# USB_USB_DWC3_53910000h register map
Vendor: Texas Instruments
Peripheral module from a debugger description file (folder AM261x).
Registers are 32-bit, read-write, reset 0x0 unless marked. A register's access mark holds for its fields unless they carry their own. Offsets are as the file gives them; lines under a group give offsets from that group; [hi:lo] are bit positions; {n}, {i} and the like mark numbered series; 'fields as' and 'values as' point back to an identical list; <NAME> marks a mode.

## USB_DWC3 (part 1 of 2)
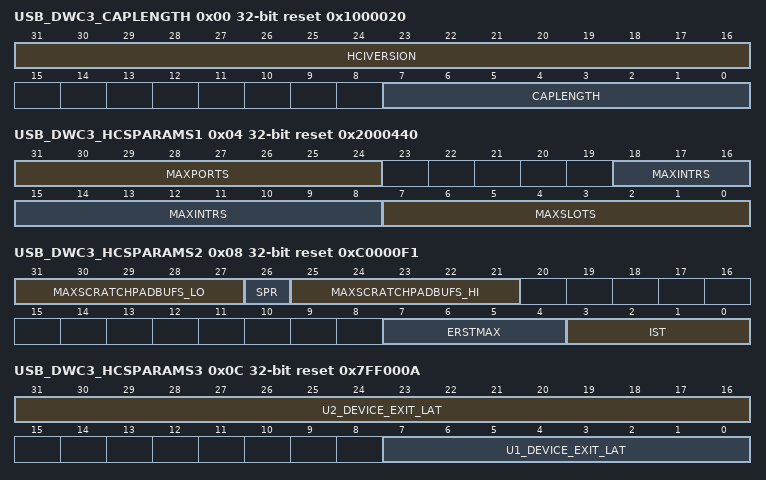
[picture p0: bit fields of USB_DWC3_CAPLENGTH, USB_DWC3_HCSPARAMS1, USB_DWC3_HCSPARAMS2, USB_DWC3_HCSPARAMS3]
0x00 USB_DWC3_CAPLENGTH ro reset 0x1000020 — Capability Registers Length + Host Controller Interface Version number.
  [31:16] HCIVERSION — Host Controller Interface Version [xHCI], in BCD. Set by FLADJ.xHCI_revision field.
  [7:0] CAPLENGTH — Capability Register Length: length of the xHCI Capabilities registers bank, in bytes
0x04 USB_DWC3_HCSPARAMS1 ro reset 0x2000440 — Host Controller Structural Parameters 1 (xHCI).
  [31:24] MAXPORTS — cf. xHCI standard
  [18:8] MAXINTRS — cf. xHCI standard
  [7:0] MAXSLOTS — cf. xHCI standard
0x08 USB_DWC3_HCSPARAMS2 ro reset 0xC0000F1 — Host Controller Structural Parameters 2 (xHCI).
  [31:27] MAXSCRATCHPADBUFS_LO — Max Scratchpad Buffers, lower bits: cf. xHCI standard
  [26] SPR — Scratchpad Restore: cf. xHCI standard
  [25:21] MAXSCRATCHPADBUFS_HI — Max Scratchpad Buffers, higher bits: cf. xHCI 1.0 standard
  [7:4] ERSTMAX — Event Ring Segment Table Max: cf. xHCI standard
  [3:0] IST — Isochronous Scheduling Threshold: cf. xHCI standard
0x0C USB_DWC3_HCSPARAMS3 ro reset 0x7FF000A — Host Controller Structural Parameters 3 (xHCI).
  [31:16] U2_DEVICE_EXIT_LAT — U2 Device Exit Latency: Worst case latency to transition from U2 to U0, in us. Applies to all root hub ports.
  [7:0] U1_DEVICE_EXIT_LAT — U1 Device Exit Latency: Worst case latency to transition a root hub Port Link State [PLS] from U1 to U0, in us.
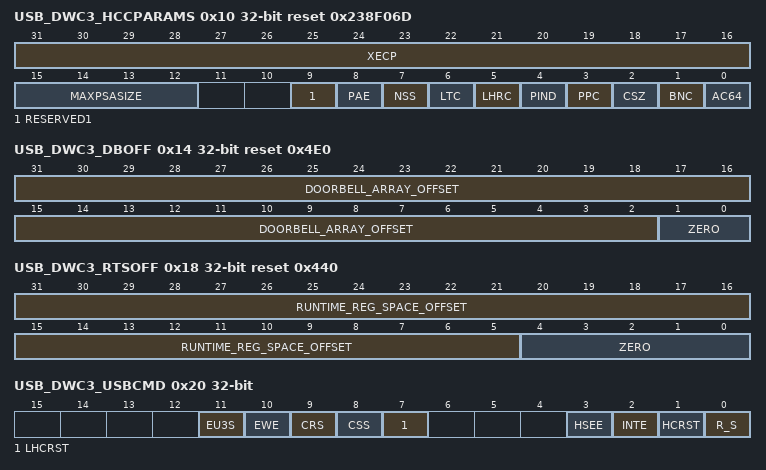
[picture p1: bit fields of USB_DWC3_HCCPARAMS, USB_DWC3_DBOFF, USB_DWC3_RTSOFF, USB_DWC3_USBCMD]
0x10 USB_DWC3_HCCPARAMS ro reset 0x238F06D — Host Controller Capability Parameters (xHCI).
  [31:16] XECP — xHCI Extended Capabilties Pointer. 32-bit dword offset, with respect to xHCI base, of the first item of the capability list.
  [15:12] MAXPSASIZE — Maximum Primary Stream Array Size: cf. xHCI standard
  [9] RESERVED1 — cf. xHCI standard
  [8] PAE — Parse All Event data: cf. xHCI 1.0 standard w errata
  [7] NSS — No Secondary SID Support cf. xHCI standard
  [6] LTC — Latency Tolerance messaging Capability cf. xHCI standard
  [5] LHRC — Light HC Reset Capability: cf. xHCI standard
  [4] PIND — Port Indicators: cf. xHCI standard
  [3] PPC — Port Power Control: cf. xHCI standard
  [2] CSZ — Context Size: cf. xHCI standard
  [1] BNC — Bandwidth Negotiation Capability: cf. xHCI standard
  [0] AC64 — 64-bit Address Capability: cf. xHCI standard
0x14 USB_DWC3_DBOFF ro reset 0x4E0 — Doorbell Offset (xHCI): Byte offset of doorbell register array (DB[0:N]), with respect to xHCI base (i.e. CAPLENGTH register).
  [31:2] DOORBELL_ARRAY_OFFSET — Byte address offset MSBits
  [1:0] ZERO — Byte address offset LSBits, always 0 [offset is 32-bit = 4-byte aligned]
0x18 USB_DWC3_RTSOFF ro reset 0x440 — RunTime Space Offset (xHCI): Byte offset of runtime register bank (starting with MFINDEX), with respect to xHCI base (i.e. CAPLENGTH register).
  [31:5] RUNTIME_REG_SPACE_OFFSET — Byte address offset MSBits
  [4:0] ZERO — Byte address offset LSBits, always 0 [offset is 32-byte aligned]
0x20 USB_DWC3_USBCMD — USB Command Register (xHCI).
  [11] EU3S — Enable U3 MFINDEX Stop: cf. xHCI standard
  [10] EWE — Enable Wrap Event: cf. xHCI standard
  [9] CRS — Controller Restore State: cf. xHCI standard
  [8] CSS — Controller Save State: cf. xHCI standard
  [7] LHCRST — Light Host Controller Reset: cf. xHCI standard
  [3] HSEE — Host System Error Enable: cf. xHCI standard
  [2] INTE — Interrupter Enable: cf. xHCI standard
  [1] HCRST — Host Controller Reset: cf. xHCI standard
  [0] R_S — Run/Stop: cf. xHCI standard
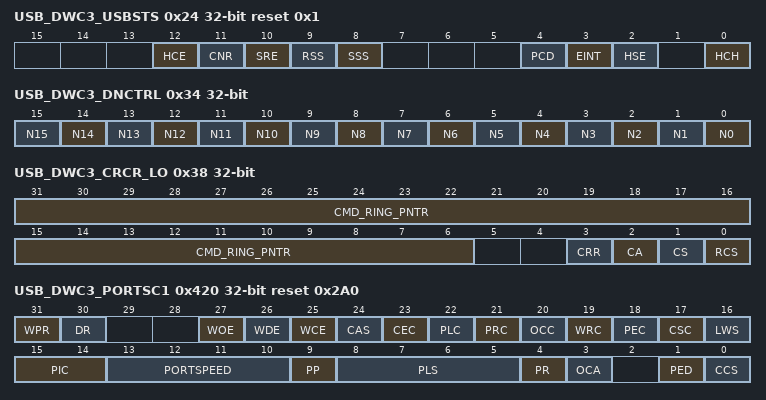
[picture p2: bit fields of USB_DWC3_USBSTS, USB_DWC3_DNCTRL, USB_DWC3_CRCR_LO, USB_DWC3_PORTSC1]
0x24 USB_DWC3_USBSTS access not given reset 0x1 — USB Status Register (xHCI).
  [12] HCE ro — Host Controller Error: cf. xHCI standard
  [11] CNR ro — Controller Not Ready [cf. xHCI standard]. Runtime or other Operational registers shall not be accessed until field is cleared. Beyond xHCI [i.e. USB host mode] functionality, indicates when the reset of the RAM is accessible, which makes the RAM-mapped registers accessible.
  [10] SRE — Save/Restore Error: cf. xHCI standard (access R/W0TC)
  [9] RSS ro — Restore State Status: cf. xHCI standard
  [8] SSS ro — Save State Status: cf. xHCI standard
  [4] PCD — Port Change Detect: cf. xHCI standard (access R/W0TC)
  [3] EINT — Event Interrupt: cf. xHCI standard (access R/W0TC)
  [2] HSE — Host System Error: cf. xHCI standard (access R/W0TC)
  [0] HCH ro — Host Controller Halted: cf. xHCI standard
0x28 USB_DWC3_PAGESIZE ro reset 0x1 — Page Size Register (xHCI).
  [15:0] PAGE_SIZE — Supported system memory page size. When bit #n is set to 1, a page size of 2^[n+12] is supported.
0x34 USB_DWC3_DNCTRL — Device Notification Control Register (xHCI).
  [n] N{n} (n=0..15) — cf. xHCI standard
0x38 USB_DWC3_CRCR_LO — Command Ring Control Register, lower half (xHCI).
  [31:6] CMD_RING_PNTR — cf. xHCI standard
  [3] CRR — cf. xHCI standard
  [2] CA — cf. xHCI standard
  [1] CS — cf. xHCI standard
  [0] RCS — cf. xHCI standard
0x3C USB_DWC3_CRCR_HI — Command Ring Control Register, upper half (xHCI).
  [31:0] CMD_RING_PNTR — cf. xHCI standard
0x50 USB_DWC3_DCBAAP_LO — Device Context Base Address Array Pointer, lower half (xHCI).
  [31:6] DEVICE_CONTEXT_BAAP — cf. xHCI standard
0x54 USB_DWC3_DCBAAP_HI — Device Context Base Address Array Pointer, upper half (xHCI).
  [31:0] DEVICE_CONTEXT_BAAP — cf. xHCI standard
0x58 USB_DWC3_CONFIG — Configure (xHCI).
  [7:0] MAXSLOTSEN — cf. xHCI standard
0x420 USB_DWC3_PORTSC1 access not given reset 0x2A0 — Port 1 (USB2) Status and Control (xHCI).
  [31] WPR — cf. xHCI standard (access R/W1TS)
  [30] DR ro — cf. xHCI standard
  [27] WOE rw — cf. xHCI standard
  [26] WDE rw — cf. xHCI standard
  [25] WCE rw — cf. xHCI standard
  [24] CAS ro — cf. xHCI standard
  [23] CEC — cf. xHCI standard (access R/W0TC)
  [22] PLC — cf. xHCI standard (access R/W0TC)
  [21] PRC — cf. xHCI standard (access R/W0TC)
  [20] OCC — cf. xHCI standard (access R/W0TC)
  [19] WRC — cf. xHCI standard (access R/W0TC)
  [18] PEC — cf. xHCI standard (access R/W0TC)
  [17] CSC — cf. xHCI standard (access R/W0TC)
  [16] LWS rw — cf. xHCI standard
  [15:14] PIC rw — cf. xHCI standard
  [13:10] PORTSPEED ro — cf. xHCI standard
  [9] PP rw — cf. xHCI standard
  [8:5] PLS rw — cf. xHCI standard
  [4] PR — cf. xHCI standard (access R/W1TS)
  [3] OCA ro — cf. xHCI standard
  [1] PED — cf. xHCI standard (access R/W0TC)
  [0] CCS ro — cf. xHCI standard
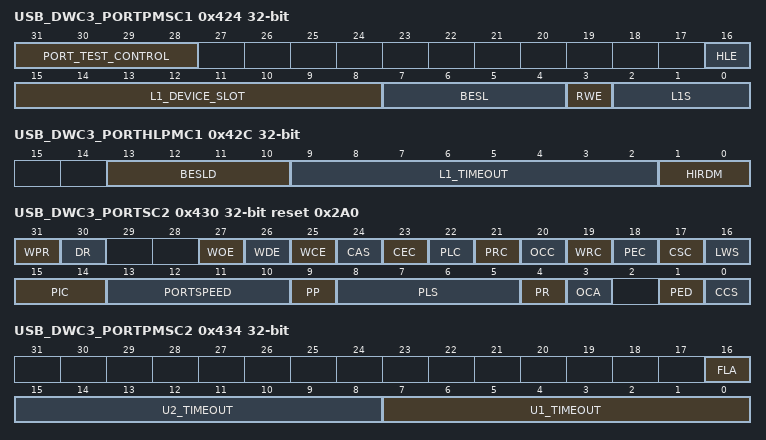
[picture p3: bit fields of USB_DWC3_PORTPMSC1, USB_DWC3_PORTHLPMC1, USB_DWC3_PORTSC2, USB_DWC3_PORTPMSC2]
0x424 USB_DWC3_PORTPMSC1 access per field — Port 1 (USB2) Power Management (LPM) Status and Control (xHCI). Field structure is protocol-dependent (here: USB2).
  [31:28] PORT_TEST_CONTROL rw — cf. xHCI standard
  [16] HLE rw — cf. xHCI standard
  [15:8] L1_DEVICE_SLOT rw — cf. xHCI standard
  [7:4] BESL rw — cf xHCI 1.0 standard w. errata
  [3] RWE rw — cf. xHCI standard
  [2:0] L1S ro — cf. xHCI standard
0x428 USB_DWC3_PORTLI1 ro — Port 1 (USB2) Link Info (xHCI).
  [15:0] LINK_ERROR_COUNT — cf. xHCI standard
0x42C USB_DWC3_PORTHLPMC1 — Port 1 (USB2) Hardware LPM Control (xHCI). Field structure is protocol-dependent (here: USB2).
  [13:10] BESLD — cf. xHCI 1.0 standard w errata
  [9:2] L1_TIMEOUT — cf. xHCI 1.0 standard w errata
  [1:0] HIRDM — cf. xHCI 1.0 standard w errata
0x430 USB_DWC3_PORTSC2 access not given reset 0x2A0 — Port 2 (USB3) Status and Control (xHCI).
  fields as USB_DWC3_PORTSC1
0x434 USB_DWC3_PORTPMSC2 — Port 2 (USB3) Power Management Status and Control (xHCI). Field structure is protocol-dependent (here: USB3).
  [16] FLA — cf. xHCI standard
  [15:8] U2_TIMEOUT — cf. xHCI standard
  [7:0] U1_TIMEOUT — cf. xHCI standard
0x438 USB_DWC3_PORTLI2 ro — Port 2 (USB3) Link Info (xHCI).
  [15:0] LINK_ERROR_COUNT — cf. xHCI standard
0x43C USB_DWC3_PORTHLPMC2 access not given reset not defined — Port 2 (USB3) Hardware LPM Control (xHCI), Field structure is protocol-dependent (here: USB3).
0x440 USB_DWC3_MFINDEX ro — Microframe Index (xHCI).
  [13:0] MICROFRAME_INDEX — cf. xHCI standard
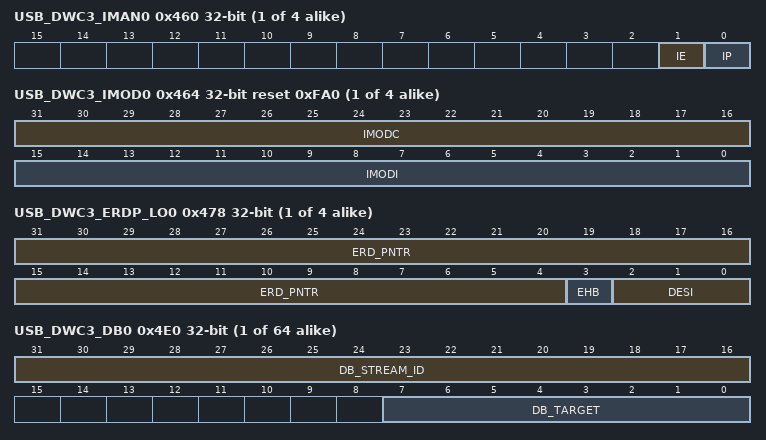
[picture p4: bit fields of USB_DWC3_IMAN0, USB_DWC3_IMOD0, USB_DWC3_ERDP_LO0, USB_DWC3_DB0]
{0x460+0x20*i} USB_DWC3_IMAN{i} access not given (i=0..3) — Interrupter Management (xHCI).
  [1] IE rw — Interrupt Enable.
  [0] IP — Interrupt Pending. Set [to 1] when: IE=1, IMODC=0, associated Event Ring is not empty, EHB=0. (access R/W0TC)
{0x464+0x20*i} USB_DWC3_IMOD{i} reset 0xFA0 (i=0..3) — Interrupter Moderation (xHCI).
  [31:16] IMODC — Interrupt Moderation Counter: Loaded to IMODI whenever IP is cleared to 0, counts down to 0, and stops. IRQ is generated when counter is 0, Event Ring is not empty, IE=1, IP=1, EHB=0. May be directly written at any time to alter the interrupt rate.
  [15:0] IMODI — Interrupt Moderation Interval: Minimum inter-IRQ interval, in 250ns increments.
{0x468+0x20*i} USB_DWC3_ERSTSZ{i} (i=0..3) — Event Ring Segment Table Size (xHCI).
  [15:0] ERS_TABLE_SIZE — cf. xHCI standard
{0x470+0x20*i} USB_DWC3_ERSTBA_LO{i} (i=0..3) — Event Ring Segment Table Base Address, lower half (xHCI).
  [31:6] ERS_TABLE_BAR — cf. xHCI standard
{0x474+0x20*i} USB_DWC3_ERSTBA_HI{i} (i=0..3) — Event Ring Segment Table Base Address, upper half (xHCI).
  [31:0] ERS_TABLE_BAR — cf. xHCI standard
{0x478+0x20*i} USB_DWC3_ERDP_LO{i} access not given (i=0..3) — Event Ring Dequeue Pointer, lower half (xHCI).
  [31:4] ERD_PNTR rw — cf. xHCI standard
  [3] EHB — cf. xHCI standard (access R/W0TC)
  [2:0] DESI rw — cf. xHCI standard
{0x47C+0x20*i} USB_DWC3_ERDP_HI{i} (i=0..3) — Event Ring Dequeue Pointer, upper half (xHCI).
  [31:0] ERD_PNTR — cf. xHCI standard
{0x4E0+4i} USB_DWC3_DB{i} (i=0..63) — Doorbell (xHCI).
  [31:16] DB_STREAM_ID — cf. xHCI standard
  [7:0] DB_TARGET — cf. xHCI standard
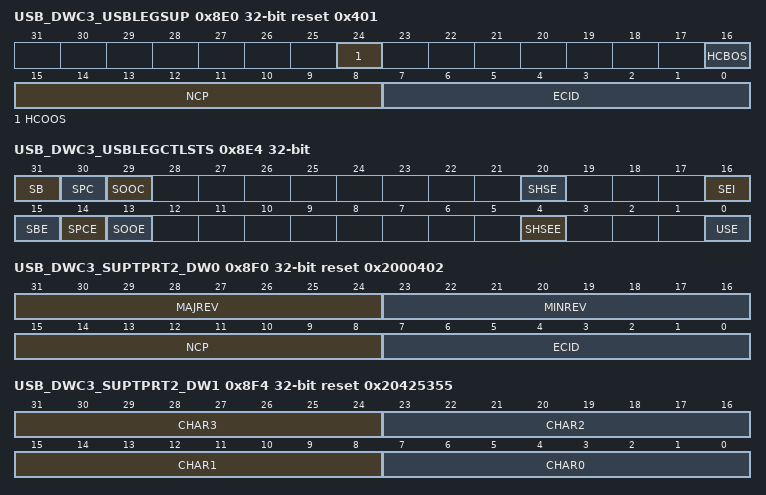
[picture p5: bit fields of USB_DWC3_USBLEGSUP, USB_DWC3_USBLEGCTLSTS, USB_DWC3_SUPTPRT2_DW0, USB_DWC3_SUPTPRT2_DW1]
0x8E0 USB_DWC3_USBLEGSUP access per field reset 0x401 — USB Legacy Support Capability.
  [24] HCOOS rw — HC OS Owned Semaphore: cf. xHCI standard
  [16] HCBOS rw — HC BIOS Owned Semaphore: cf. xHCI standard
  [15:8] NCP ro — Next Capability Pointer: 32-bit dword offset of the next capability.
  [7:0] ECID ro — Extended Capability ID code [descriptor size, in bytes]
0x8E4 USB_DWC3_USBLEGCTLSTS access not given — USB Legacy Control / Status.
  [31] SB — cf. xHCI standard (access R/W0TC)
  [30] SPC — cf. xHCI standard (access R/W0TC)
  [29] SOOC — cf. xHCI standard (access R/W0TC)
  [20] SHSE ro — cf. xHCI standard
  [16] SEI ro — cf. xHCI standard
  [15] SBE rw — cf. xHCI standard
  [14] SPCE rw — cf. xHCI standard
  [13] SOOE rw — cf. xHCI standard
  [4] SHSEE rw — cf. xHCI standard
  [0] USE rw — cf. xHCI standard
0x8F0 USB_DWC3_SUPTPRT2_DW0 ro reset 0x2000402 — Supported protocol capability USB2, 32-bit dword #0
  [31:24] MAJREV — Major Revision, BCD-encoded
  [23:16] MINREV — Minor Revision, BCD-encoded
  [15:8] NCP — Next Capability Pointer: 32-bit dword offset of the next capability.
  [7:0] ECID — Extended Capability ID code [descriptor size, in bytes]
0x8F4 USB_DWC3_SUPTPRT2_DW1 ro reset 0x20425355 — Supported protocol capability USB2, 32-bit dword #1: Name String 'USB '
  [31:24] CHAR3 — ASCII ' ' [space]
  [23:16] CHAR2 — ASCII 'B'
  [15:8] CHAR1 — ASCII 'S'
  [7:0] CHAR0 — ASCII 'U'
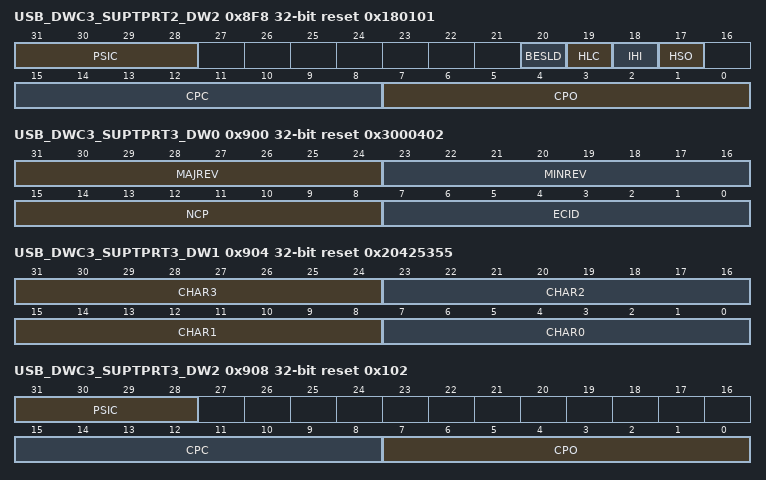
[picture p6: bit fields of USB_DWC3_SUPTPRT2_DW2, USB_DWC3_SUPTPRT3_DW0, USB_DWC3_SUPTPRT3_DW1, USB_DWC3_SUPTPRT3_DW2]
0x8F8 USB_DWC3_SUPTPRT2_DW2 ro reset 0x180101 — Supported protocol capability USB2, 32-bit dword #2
  [31:28] PSIC — Port Speed ID Count. Reserved in xHCI 0.96
  [20] BESLD — BESL decoding capability [LPM Errata]
  [19] HLC — Hardware LPM Capability.
  [18] IHI — Integrated Hub Implemented.
  [17] HSO — High-Speed Only
  [15:8] CPC — Compatible Port Count: Number of consecutive ports of the root hub that support this protocol, from CPO to CPO+CPC-1
  [7:0] CPO — Compatible Port Offset: Starting port number of root hub port[s] that support this protocol.
0x8FC USB_DWC3_SUPTPRT2_DW3 ro — Supported protocol capability USB2, 32-bit dword #3
  [4:0] PST — Protocol Slot Type, cf. xHCI 1.0 standard w errata
0x900 USB_DWC3_SUPTPRT3_DW0 ro reset 0x3000402 — Supported protocol capability USB3, 32-bit dword #0
  fields as USB_DWC3_SUPTPRT2_DW0
0x904 USB_DWC3_SUPTPRT3_DW1 ro reset 0x20425355 — Supported protocol capability USB3, 32-bit dword #1: Name String 'USB '
  fields as USB_DWC3_SUPTPRT2_DW1
0x908 USB_DWC3_SUPTPRT3_DW2 ro reset 0x102 — Supported protocol capability USB3, 32-bit dword #2
  [31:28] PSIC — Port Speed ID Count. Reserved in xHCI 0.96
  [15:8] CPC — Compatible Port Count: Number of consecutive ports of the root hub that support this protocol, from CPO to CPO+CPC-1
  [7:0] CPO — Compatible Port Offset: Starting port number of root hub port[s] that support this protocol.
0x90C USB_DWC3_SUPTPRT3_DW3 ro — Supported protocol capability USB3, 32-bit dword #3
  [4:0] PST — Protocol Slot Type, cf. xHCI 1.0 standard w errata
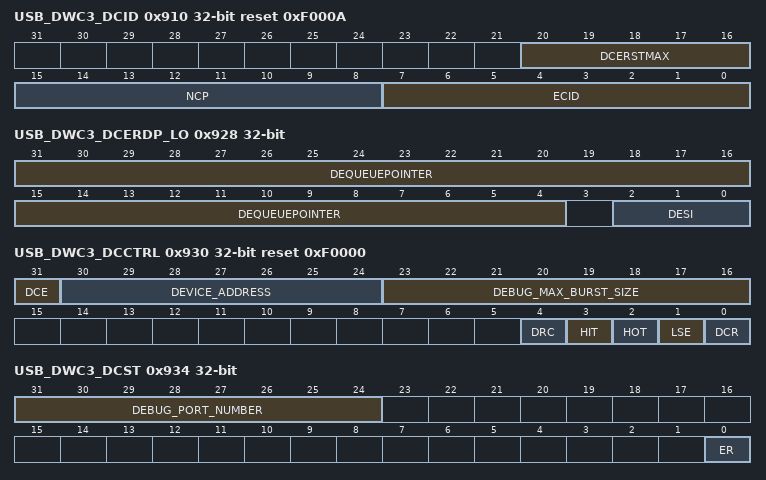
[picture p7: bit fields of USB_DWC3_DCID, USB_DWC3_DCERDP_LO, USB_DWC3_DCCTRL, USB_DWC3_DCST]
0x910 USB_DWC3_DCID ro reset 0xF000A — Debug Capability ID (cf. xHCI 1.0 standard, DbC).
  [20:16] DCERSTMAX — Debug Capability Event Ring Segment Table Maximum size == 2^[DCERSTMAX] entries
  [15:8] NCP — Next Capability Pointer: 32-bit dword offset of the next capability.
  [7:0] ECID — Extended Capability ID code [descriptor size, in bytes]
0x914 USB_DWC3_DCDB — Debug Capability Door-Bell (cf. xHCI 1.0 standard, DbC).
  [15:8] DBTARGET — Door-Bell Target
0x918 USB_DWC3_DCERSTSZ — Debug Capability Event Ring Segment Table Size (cf. xHCI 1.0 standard, DbC).
  [15:0] TABLESIZE — Event Ring Segment Table Size
0x920 USB_DWC3_DCERSTBA_LO — Debug Capability Event Ring Segment Table Base Address, low bits (cf. xHCI 1.0 standard, DbC).
  [31:4] BASEADDRESS — DCERSTBA[31:4]
0x924 USB_DWC3_DCERSTBA_HI — Debug Capability Event Ring Segment Table Base Address, high bits (cf. xHCI 1.0 standard, DbC).
  [31:0] BASEADDRESS — DCERSTBA[63:32]
0x928 USB_DWC3_DCERDP_LO — Debug Capability Event Ring Dequeue Pointer, low bits (cf. xHCI 1.0 standard, DbC).
  [31:4] DEQUEUEPOINTER — DCERDP[31:4]
  [2:0] DESI — Dequeue ERST Segment Index
0x92C USB_DWC3_DCERDP_HI — Debug Capability Event Ring Dequeue Pointer, high bits (cf. xHCI 1.0 standard, DbC).
  [31:0] DEQUEUEPOINTER — DCERDP[63:32]
0x930 USB_DWC3_DCCTRL access not given reset 0xF0000 — Debug Capability Control (cf. xHCI 1.0 standard, DbC).
  [31] DCE rw — Debug Capability Enable
  [30:24] DEVICE_ADDRESS ro
  [23:16] DEBUG_MAX_BURST_SIZE ro — Debug Maximum Burst Size
  [4] DRC — DbC Run Change (access R/W0TC)
  [3] HIT — Halt IN TR (access R/W1TS)
  [2] HOT — Halt Out TR (access R/W1TS)
  [1] LSE rw — Link Status Event Enable
  [0] DCR ro — Debug Capability Run
0x934 USB_DWC3_DCST ro — Debug Capability Status (cf. xHCI 1.0 standard, DbC).
  [31:24] DEBUG_PORT_NUMBER
  [0] ER — Event Ring not empty
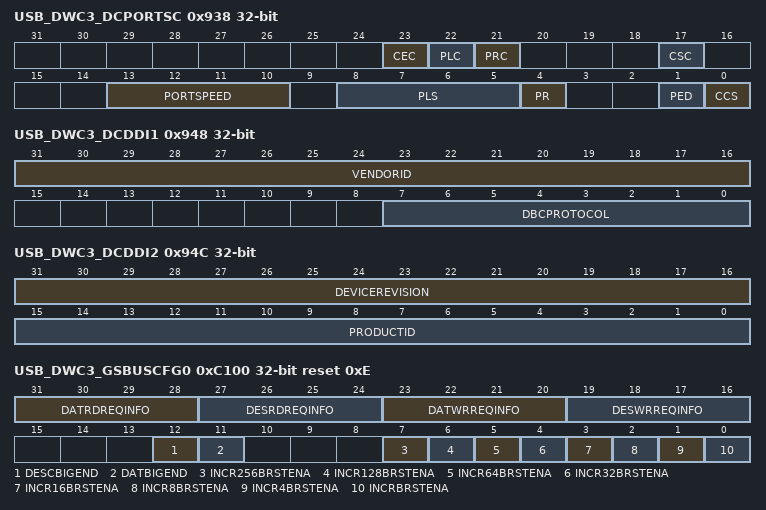
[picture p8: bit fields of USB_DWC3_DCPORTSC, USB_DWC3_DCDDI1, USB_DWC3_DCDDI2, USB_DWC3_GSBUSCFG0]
0x938 USB_DWC3_DCPORTSC access not given — Debug Capability Port Status & Control (cf. xHCI 1.0 standard, DbC).
  [23] CEC — port Config Error Change (access R/W0TC)
  [22] PLC — Port Link status Change (access R/W0TC)
  [21] PRC — Port Reset Change (access R/W0TC)
  [17] CSC — Connect Status Change (access R/W0TC)
  [13:10] PORTSPEED ro
  [8:5] PLS ro — Port Link State
  [4] PR ro — Port Reset
  [1] PED rw — Port Enable / Disable
  [0] CCS ro — Current Connect Status
0x940 USB_DWC3_DCCP_LO — Debug Capability Context Pointer, low bits (cf. xHCI 1.0 standard, DbC).
  [31:4] CONTEXTPOINTER — DCCP[31:4]
0x944 USB_DWC3_DCCP_HI — Debug Capability Context Pointer, high bits (cf. xHCI 1.0 standard, DbC).
  [31:0] CONTEXTPOINTER — DCCP[64:32]
0x948 USB_DWC3_DCDDI1 — Debug Capability Device Descriptor Info #1 (cf. xHCI 1.0 standard, DbC).
  [31:16] VENDORID — Vendor ID = USB descriptor field 'idVendor'
  [7:0] DBCPROTOCOL — DbC Protocol = USB descriptor field 'bInterfaceProtocol'
0x94C USB_DWC3_DCDDI2 — Debug Capability Device Descriptor Info #2 (cf. xHCI 1.0 standard, DbC).
  [31:16] DEVICEREVISION — Device Revision = USB descriptor field 'bcdDevice'
  [15:0] PRODUCTID — Product ID = USB descriptor field 'bcdDevice'
0xC100 USB_DWC3_GSBUSCFG0 reset 0xE — Global SoC Bus Configuration Register 0
  [31:28] DATRDREQINFO — AXI cache type for DATA reads [AXI3 arcache[3:0]]. In host mode, bit 1 [cacheable] is replaced by [inverted] TRB no-snoop flag
  [27:24] DESRDREQINFO — AXI cache type for DESCRIPTOR reads [AXI3 arcache[3:0]]. In host mode, bit 1 [cacheable] is replaced by [inverted] DMA command's no-snoop flag
  [23:20] DATWRREQINFO — AXI cache type for DATA writes [AXI3 awcache[3:0]]. In host mode, bit 1 [cacheable] is replaced by [inverted] TRB no-snoop flag
  [19:16] DESWRREQINFO — AXI cache type for DESCRIPTOR writes [AXI3 awcache[3:0]]. In host mode, bit 1 [cacheable] is replaced by [inverted] DMA command's no-snoop flag
  [12] DESCBIGEND — Endian mode for descriptor accesses.
  [11] DATBIGEND — Endian mode for data accesses.
  [7] INCR256BRSTENA — INCR256 Burst Type Enable. 256*64/8= 2-kByte burst.
  [6] INCR128BRSTENA — INCR128 Burst Type Enable. 128*64/8= 1-kByte burst.
  [5] INCR64BRSTENA — INCR64 Burst Type Enable. 64*64/8= 512-Byte burst.
  [4] INCR32BRSTENA — INCR32 Burst Type Enable. 32*64/8= 256-Byte burst.
  [3] INCR16BRSTENA — INCR16 Burst Type Enable. 16*64/8= 128-Byte burst.
  [2] INCR8BRSTENA — INCR8 Burst Type Enable. 8*64/8= 64-Byte burst.
  [1] INCR4BRSTENA — INCR4 Burst Type Enable. 4*64/8= 32-Byte burst: RECOMMENDED. Enables bursts of beat length 1, 2, 3, 4, and prevents [16-byte] descriptor accesses from being broken up: highly recommended.
  [0] INCRBRSTENA — Undefined Length INCR Burst Type Enable: DO NOT ENABLE. When enabled, this has higher priority than other burst types.
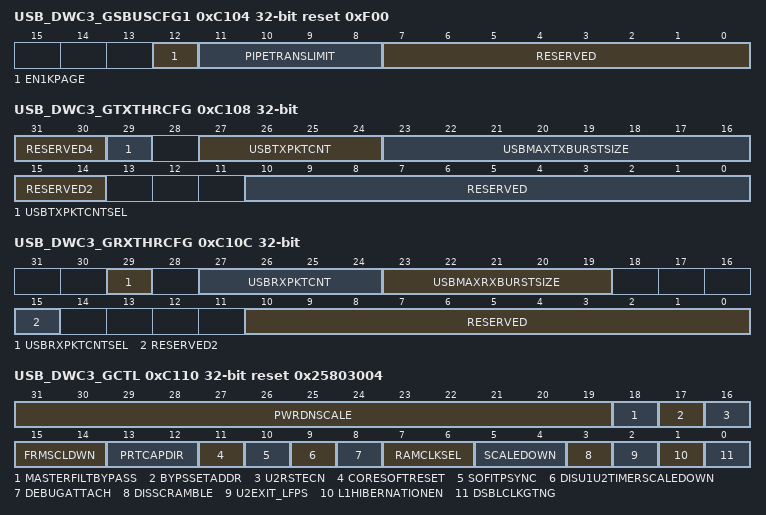
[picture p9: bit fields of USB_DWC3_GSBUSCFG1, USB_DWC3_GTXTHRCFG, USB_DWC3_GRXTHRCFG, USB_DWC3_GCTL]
0xC104 USB_DWC3_GSBUSCFG1 access per field reset 0xF00 — Global SoC Bus Configuration Register 1
  [12] EN1KPAGE rw — 1k-page Boundary Enable
  [11:8] PIPETRANSLIMIT rw — Maximum number of outstanding [read or write] pipelined sequential [i.e. in-order] transaction requests on the master interface [field value+1]
  [7:0] RESERVED ro — Always write 0, result of Writing of a non-zero value is undetermined.
0xC108 USB_DWC3_GTXTHRCFG access per field — Global Tx Threshold Control Register. Valid only in Host mode.
  [31:30] RESERVED4 ro — Always write 0, result of Writing of a non-zero value is undetermined.
  [29] USBTXPKTCNTSEL rw — USB Transmit Packet Count Enable: Enables/disables USB trasnmission multi-packet thresholding
  [27:24] USBTXPKTCNT rw — USB Transmit Packet Count : Number of packets that must be in the TXFIFO before transmission for the corresponding USB transaction [burst] can start. Don't care if USBTxPktCntSel=0.
  [23:16] USBMAXTXBURSTSIZE rw — USB Maximum Transmit Burst Size. Max OUT burst size, when USBTxPktCntSel=1. Avoids TX FIFO underrun when the system bus is slower than the USB. Only applies to SS Bulk / Iso / Int OUT endpoints in host mode. Don't care if USBTxPktCntSel=0.
  [15:14] RESERVED2 ro — Always write 0, result of Writing of a non-zero value is undetermined.
  [10:0] RESERVED ro — Always write 0, result of Writing of a non-zero value is undetermined.
0xC10C USB_DWC3_GRXTHRCFG access per field — Global Rx Threshold Control Register. Valid only in Host mode.
  [29] USBRXPKTCNTSEL rw — USB ReceivePacket Count Enable. Enables/disables USB reception multi-packet thresholding
  [27:24] USBRXPKTCNT rw — USB Receive Packet Count: Number of packets that must be available in the RX FIFO before the core can start the corresponding USB RX transaction [burst].Don't care if USBRxPktCntSel=0.
  [23:19] USBMAXRXBURSTSIZE rw — USB Maximum Receive Burst Size. Maxi IN burst size, when USBRxPktCntSel = 1. When the system bus is slower than the USB, RX FIFO can overrun during a long burst. User can program a smaller value to this field to limit the RX burst size that the core can do. Only applies to SS Bulk / Iso / Int IN endpoints in host mode. Don't care if USBRxPktCntSel=0.
  [15] RESERVED2 ro — Always write 0, result of Writing of a non-zero value is undetermined.
  [10:0] RESERVED ro — Always write 0, result of Writing of a non-zero value is undetermined.
0xC110 USB_DWC3_GCTL access per field reset 0x25803004 — Global Control Register.
  [31:19] PWRDNSCALE rw — Power Down Scale: In P3 state, pipe clock stops and is replaced internally by the suspend clock to create a 16kHz reference. Set field to Fs/16k, rounded up, with Fp suspend clock frequency. Required accuracy is 0-50%
  [18] MASTERFILTBYPASS rw — Master Filter Bypass. Bypasses the double-synchronizers and the 5 ms debounce filters on UTMI+ inputs [the latter are not implemented].
  [17] BYPSSETADDR rw — Override of the device address, bypassing the SET ADDRESS control transfer. For simulation only.
  [16] U2RSTECN rw — If the super speed connection fails during POLL or LMP exchange, the device connects at non-SS mode. If this bit is set, then device attempts three more times to connect at SS, even if it previously failed to operate in SS mode.
  [15:14] FRMSCLDWN rw — Frame scale-down. This field scales down device view of a SOF [FS/LS] / uSOF [HS] / ITP [SS] duration.
  [13:12] PRTCAPDIR rw — Port Capability Direction
  [11] CORESOFTRESET rw — Core Soft Reset. When you reset PHYs [using GUBS3PHYCFG or GUSB3PIPECTL registers], you must keep the core in reset state until PHY clocks are stable.
  [10] SOFITPSYNC rw — Not supported: always write 0
  [9] DISU1U2TIMERSCALEDOWN rw — Disable scaledown on U1/U2 timer [when general scaledown is enabled in GCTL[5:4]]. For simulation only.
  [8] DEBUGATTACH rw — Debug Attach. When this bit is set: a] SS Link proceeds directly to the Polling link state [after RUN/STOP in the DCTL register is asserted] without checking remote termination. b] Link LFPS polling timeout is infinite c] Polling timeout during TS1 is infinite [in case link is waiting for TXEQ to finish].
  [7:6] RAMCLKSEL rw — RAM Clock Select. No action, hardware always uses bus clock [config 2'b00]
  [5:4] SCALEDOWN rw — Scale-Down Mode Enable. Switches to shorter, non-standard protocol time intervals to speed up simulation. DO NOT MODIFY ON ACTUAL HARDWARE.
  [3] DISSCRAMBLE rw — Disable Scrambling. Transmit request to Link Partner on next transition to Recovery or Polling.
  [2] U2EXIT_LFPS rw — U2 exit LFPS timer threshold setup
  [1] L1HIBERNATIONEN ro — HIBERNATION / SAR FEATURE NOT IMPLEMENTED
  [0] DSBLCLKGTNG rw — Disable Clock Gating. When this bit is set to 1 and the core is in Low Power mode, internal clock gating is disabled.
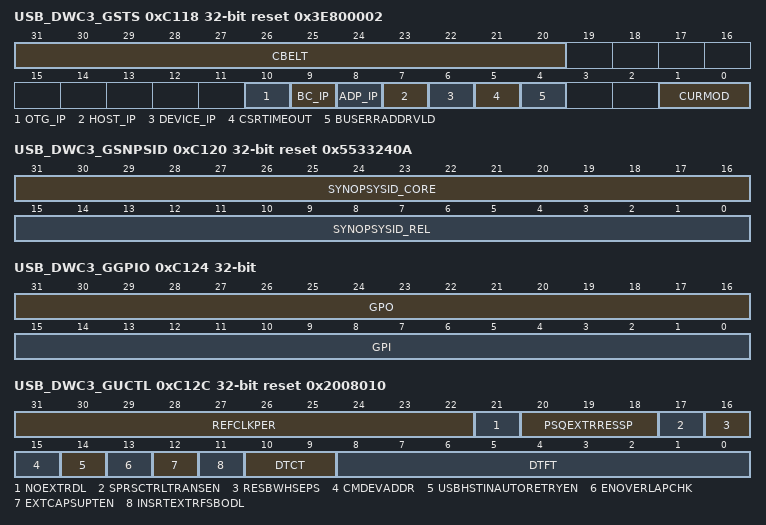
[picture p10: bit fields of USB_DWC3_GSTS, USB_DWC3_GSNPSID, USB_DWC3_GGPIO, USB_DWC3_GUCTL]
0xC118 USB_DWC3_GSTS access per field reset 0x3E800002 — Global Status Register.
  [31:20] CBELT ro — Current BELT Value. In Host mode, this field indicates the minimum value of all received device BELT values and the BELT value that is set by the Set Latency Tolerance Value command.
  [10] OTG_IP ro — OTG interrupt status
  [9] BC_IP ro — Battery Charger interrupt status: NOT IMPLEMENTED
  [8] ADP_IP ro — ADP interrupt status: NOT IMPLEMENTED
  [7] HOST_IP ro — Host interrupt status
  [6] DEVICE_IP ro — Device interrupt status
  [5] CSRTIMEOUT rw — Control/Status Register access Timeout status flag.
  [4] BUSERRADDRVLD rw — Bus Error Address Valid status flag. Also flagged on USBSTS.HSE field [host mode] and DEPEVT[12] on XferComplete/XferInProgress event [device mode].
  [1:0] CURMOD ro — Current Mode of Operation.
0xC120 USB_DWC3_GSNPSID ro reset 0x5533240A — Synopsys ID: Core Identification and Release number. Software uses this register to configure release-specific features in the driver.
  [31:16] SYNOPSYSID_CORE — SYNOPSYSID MSBytes: core identifier
  [15:0] SYNOPSYSID_REL — SYNOPSYSID LSBytes: version number. For instance, version 1.00a => 0x100A
0xC124 USB_DWC3_GGPIO access per field — Global General Purpose Input/Output Register.
  [31:16] GPO rw — General Purpose Output. DO NOT USE: NOT CONNECTED.
  [15:0] GPI ro — General Purpose Inputs. TIED LOW.
0xC128 USB_DWC3_GUID — Global User ID Register.
  [31:0] USERID — Application-programmable ID field.
0xC12C USB_DWC3_GUCTL reset 0x2008010 — Global User Control Register.
  [31:22] REFCLKPER — Feature not implemented, do not change reset value.
  [21] NOEXTRDL — No Extra Delay between SOF and the 1st packet [when host]
  [20:18] PSQEXTRRESSP — Protocol Status Queue Extra Reserved Space [Debug only]. Additional space in the PSQ reserved before the USB3 protocl transaction layer [U3PTL] initiates a new USB transaction and burst beats.
  [17] SPRSCTRLTRANSEN — Sparse Control Transaction Enable. Valid in host mode only [any speed].
  [16] RESBWHSEPS — Reserving [more] Bandwidth for HS Periodic EPs. Valid in host mode only.
  [15] CMDEVADDR — Compliance Mode for Device Address. Valid in host mode only.
  [14] USBHSTINAUTORETRYEN — Host IN Auto Retry Enable: host core behaviour upon data packet CRC errors or internal overrun scenarios in non-isochronous IN transfers.
  [13] ENOVERLAPCHK — Enable Check for LFPS Overlap During Remote U1/U2/U3 Exit
  [12] EXTCAPSUPTEN — External Extended Capability Support Enable
  [11] INSRTEXTRFSBODL — Insert Extra Delay Between FS Bulk OUT Transactions
  [10:9] DTCT — Device Timeout Coarse Tuning: time the host waits for a response from device before timeout. Coarse setting.
  [8:0] DTFT — Device Timeout Fine Tuning: time the host waits for a response from device before timeout. Fine setting. Timer runs on the 125 MHz clock [8 ns period], timeout is DTFT * 256 * 8 ns ~= DTFT * 2 us. Don't care unless DTCT=0
0xC130 USB_DWC3_GBUSERRADDRLO ro — Global Bus Error (non-precise) Address, LSbits: Base address of the first system bus DMA transfer that got a bus error. Note that each DMA transfer can contain several bursts, each spanning several addresses. Valid when GSTS.BusErrAddrVld=1. Cleared upon core reset.
  [31:0] BUSERRADDRLO — BUSERRADDR[31:0]
0xC134 USB_DWC3_GBUSERRADDRHI ro — Global Bus Error (non-precise) Address, MSbits: Base address of the first system bus DMA transfer that got a bus error. Note that each DMA transfer can contain several bursts, each spanning several addresses. Valid when GSTS.BusErrAddrVld=1. Cleared upon core reset.
  [31:0] BUSERRADDRHI — BUSERRADDR[63:32]
0xC138 USB_DWC3_GPRTBIMAPLO — Global Port-to-SS USB Instance Mapping, low bits [31:0].
  [3:0] BINUM1 — SS USB Instance Number for Port number 1. Application-programmable ID field.
0xC13C USB_DWC3_GPRTBIMAPHI access not given reset not defined — Global Port-to-SS USB Instance Mapping, high bits [63:32].
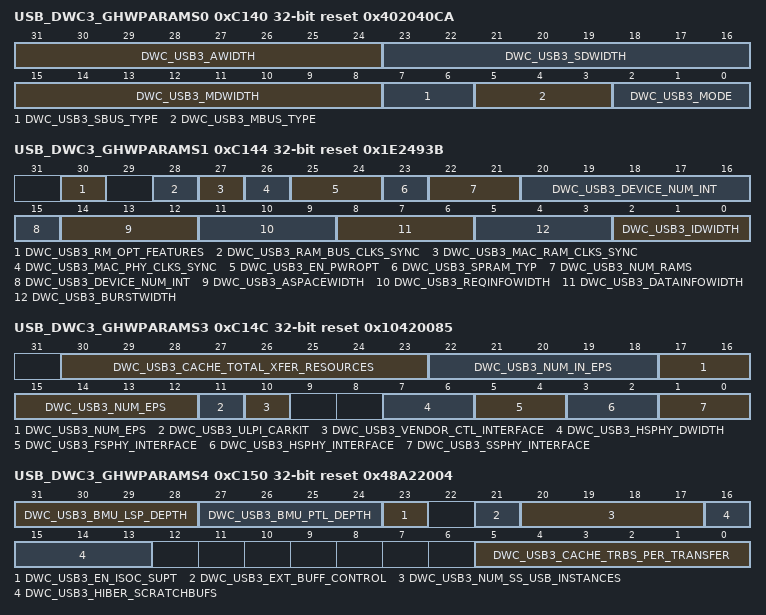
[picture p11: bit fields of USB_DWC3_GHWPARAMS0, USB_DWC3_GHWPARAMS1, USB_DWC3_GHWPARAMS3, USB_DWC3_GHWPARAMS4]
0xC140 USB_DWC3_GHWPARAMS0 ro reset 0x402040CA — Global hardware parameters #0
  [31:24] DWC_USB3_AWIDTH — Global hardware configuration parameter DWC_USB3_AWIDTH: [Master] Address Width [in bits]
  [23:16] DWC_USB3_SDWIDTH — Global hardware configuration parameter DWC_USB3_SDWIDTH: Target Data Width [in bits]
  [15:8] DWC_USB3_MDWIDTH — Global hardware configuration parameter DWC_USB3_MDWIDTH: Master Data Width [in bits]
  [7:6] DWC_USB3_SBUS_TYPE — Global hardware configuration parameter DWC_USB3_SBUS_TYPE: [System bus] Target type
  [5:3] DWC_USB3_MBUS_TYPE — Global hardware configuration parameter DWC_USB3_MBUS_TYPE: [System bus] Master type
  [2:0] DWC_USB3_MODE — Global hardware configuration parameter DWC_USB3_MODE
0xC144 USB_DWC3_GHWPARAMS1 ro reset 0x1E2493B — Global hardware parameters #1
  [30] DWC_USB3_RM_OPT_FEATURES — Global hardware configuration parameter DWC_USB3_RM_OPT_FEATURES: Remove Optional Features
  [28] DWC_USB3_RAM_BUS_CLKS_SYNC — Global hardware configuration parameter DWC_USB3_RAM_BUS_CLKS_SYNC: RAM vs. BUS clocks synchronous ?
  [27] DWC_USB3_MAC_RAM_CLKS_SYNC — Global hardware configuration parameter DWC_USB3_MAC_RAM_CLKS_SYNC: MAC vs. RAM clocks synchronous ?
  [26] DWC_USB3_MAC_PHY_CLKS_SYNC — Global hardware configuration parameter DWC_USB3_MAC_PHY_CLKS_SYNC: MAC vs. PHY clocks synchronous ?
  [25:24] DWC_USB3_EN_PWROPT — Global hardware configuration parameter DWC_USB3_EN_PWROPT: Power optimization
  [23] DWC_USB3_SPRAM_TYP — Global hardware configuration parameter DWC_USB3_SPRAM_TYP
  [22:21] DWC_USB3_NUM_RAMS — Global hardware configuration parameter DWC_USB3_NUM_RAMS: Number of internal RAMs
  [20:15] DWC_USB3_DEVICE_NUM_INT — Global hardware configuration parameter DWC_USB3_DEVICE_NUM_INT: Number of interrupts [and event buffers] in device mode
  [14:12] DWC_USB3_ASPACEWIDTH — Global hardware configuration parameter DWC_USB3_ASPACEWIDTH
  [11:9] DWC_USB3_REQINFOWIDTH — Global hardware configuration parameter DWC_USB3_REQINFOWIDTH
  [8:6] DWC_USB3_DATAINFOWIDTH — Global hardware configuration parameter DWC_USB3_DATAINFOWIDTH
  [5:3] DWC_USB3_BURSTWIDTH — Global hardware configuration parameter DWC_USB3_BURSTWIDTH minus one, fixed to 8-1=7
  [2:0] DWC_USB3_IDWIDTH — Global hardware configuration parameter DWC_USB3_IDWIDTH minus 1. Note: Sets only the master port's ID width. Target ID width is set by non-readable DWC_USB3_SIDWIDTH
0xC148 USB_DWC3_GHWPARAMS2 ro — Global hardware parameters #2
  [31:0] DWC_USB3_USERID — Global hardware configuration parameter DWC_USB3_USERID
0xC14C USB_DWC3_GHWPARAMS3 ro reset 0x10420085 — Global hardware parameters #3
  [30:23] DWC_USB3_CACHE_TOTAL_XFER_RESOURCES — Global hardware configuration parameter DWC_USB3_NUM_CACHE_TOTAL_XFER_RESOURCES: Cache total transfer resources
  [22:18] DWC_USB3_NUM_IN_EPS — Global hardware configuration parameter DWC_USB3_NUM_IN_EPS: Number of IN endpoints, with EP0 counting as one.
  [17:12] DWC_USB3_NUM_EPS — Global hardware configuration parameter DWC_USB3_NUM_EPS: Total number of endpoints [IN+OUT, with EP0 counting as 2 separate ones]
  [11] DWC_USB3_ULPI_CARKIT — Global hardware configuration parameter DWC_USB3_ULPI_CARKIT: ULPI [optional] car-kit mode implementation
  [10] DWC_USB3_VENDOR_CTL_INTERFACE — Global hardware configuration parameter DWC_USB3_VENDOR_CTL_INTERFACE: [UTMI] Vendor Control i/f implementation
  [7:6] DWC_USB3_HSPHY_DWIDTH — Global hardware configuration parameter DWC_USB3_HSPHY_DWIDTH: HS PHY data width
  [5:4] DWC_USB3_FSPHY_INTERFACE — Global hardware configuration parameter DWC_USB3_FSPHY_INTERFACE: Full [/Low]-Speed [serial] PHY interface
  [3:2] DWC_USB3_HSPHY_INTERFACE — Global hardware configuration parameter DWC_USB3_HSPHY_INTERFACE: High-speed PHY interface
  [1:0] DWC_USB3_SSPHY_INTERFACE — Global hardware configuration parameter DWC_USB3_SSPHY_INTERFACE: Super Speed PHY interface.
0xC150 USB_DWC3_GHWPARAMS4 ro reset 0x48A22004 — Global hardware parameters #4
  [31:28] DWC_USB3_BMU_LSP_DEPTH — Global hardware configuration parameter DWC_USB3_BMU_LSP_DEPTH: Bus Management Unit / List Processor buffer depth
  [27:24] DWC_USB3_BMU_PTL_DEPTH — Global hardware configuration parameter DWC_USB3_BMU_PTL_DEPTH: Bus Management Unit / Protocol Transaction Layer buffer depth
  [23] DWC_USB3_EN_ISOC_SUPT — Global hardware configuration parameter DWC_USB3_EN_ISOC_SUPT: Enable Isochronous Support
  [21] DWC_USB3_EXT_BUFF_CONTROL — Global hardware configuration parameter DWC_USB3_EXT_BUFF_CONTROL: External Buffer Control
  [20:17] DWC_USB3_NUM_SS_USB_INSTANCES — Global hardware configuration parameter DWC_USB3_NUM_SS_USB_INSTANCES: Number of [independent] SS USB schedulers
  [16:13] DWC_USB3_HIBER_SCRATCHBUFS — Global hardware configuration parameter DWC_USB3_HIBER_SCRATCHBUFS: Number of 4kbyte buffers required in system memory to store context during hibernation. Don't care since hibernation is not enabled.
  [5:0] DWC_USB3_CACHE_TRBS_PER_TRANSFER — Global hardware configuration parameter DWC_USB3_CACHE_TRBS_PER_TRANSFER
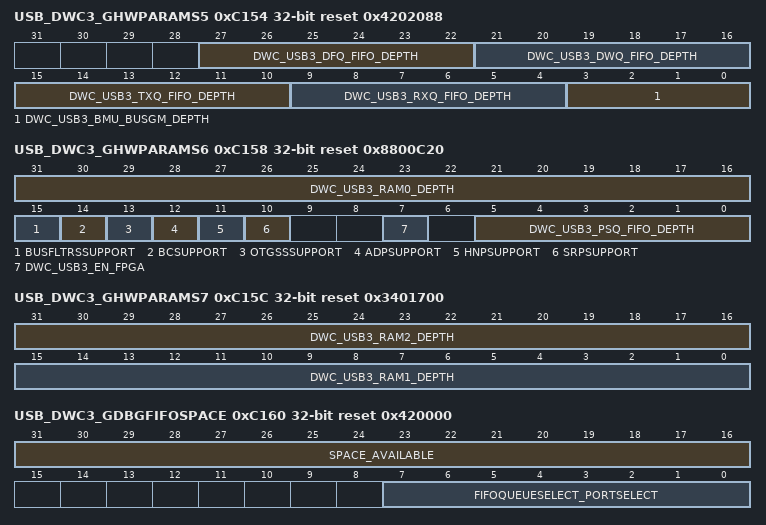
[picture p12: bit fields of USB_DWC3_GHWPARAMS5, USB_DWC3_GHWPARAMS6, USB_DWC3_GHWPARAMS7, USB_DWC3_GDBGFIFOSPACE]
0xC154 USB_DWC3_GHWPARAMS5 ro reset 0x4202088 — Global hardware parameters #5
  [27:22] DWC_USB3_DFQ_FIFO_DEPTH — Global hardware configuration parameter DWC_USB3_DFQ_FIFO_DEPTH
  [21:16] DWC_USB3_DWQ_FIFO_DEPTH — Global hardware configuration parameter DWC_USB3_DWQ_FIFO_DEPTH
  [15:10] DWC_USB3_TXQ_FIFO_DEPTH — Global hardware configuration parameter DWC_USB3_TXQ_FIFO_DEPTH
  [9:4] DWC_USB3_RXQ_FIFO_DEPTH — Global hardware configuration parameter DWC_USB3_RXQ_FIFO_DEPTH
  [3:0] DWC_USB3_BMU_BUSGM_DEPTH — Global hardware configuration parameter DWC_USB3_BMU_BUSGM_DEPTH
0xC158 USB_DWC3_GHWPARAMS6 ro reset 0x8800C20 — Global hardware parameters #6
  [31:16] DWC_USB3_RAM0_DEPTH — Depth of RAM#0, in 64-bit words. RAM0 contains descriptor cache and MMR.
  [15] BUSFLTRSSUPPORT — Filtering [debounce] on OTG UTMI+ inputs [iddig,vbusvalid,avalid,bvalid,sessend]. Reflects DWC_USB3_EN_OTG_FILTERS.
  [14] BCSUPPORT — Battery Charger detection [ACA = Accessory Charger Adapter] support implemented internally. Reflects DWC_USB3_EN_BC. Note: Support can also be provided OUTSIDE the controller.
  [13] OTGSSSUPPORT — OTG SuperSpeed support [aka OTG3.0]
  [12] ADPSUPPORT — OTG2.0 ADP [Attach Detection Protocol] support implemented internally. Reflects DWC_USB3_EN_ADP. Note: Support can also be provided OUTSIDE the controller.
  [11] HNPSUPPORT — OTG2.0 HNP [Host Negotiation Protocol] support. Set when in DRD mode.
  [10] SRPSUPPORT — OTG2.0 SRP [Session Request Protocol] support.
  [7] DWC_USB3_EN_FPGA — Global hardware configuration parameter DWC_USB3_EN_FPGA
  [5:0] DWC_USB3_PSQ_FIFO_DEPTH — Global hardware configuration parameter DWC_USB3_PSQ_FIFO_DEPTH
0xC15C USB_DWC3_GHWPARAMS7 ro reset 0x3401700 — Global hardware parameters #7
  [31:16] DWC_USB3_RAM2_DEPTH — Depth of RAM#2, in 64-bit words. RAM2 contains Rx FIFOs.
  [15:0] DWC_USB3_RAM1_DEPTH — Depth of RAM#1, in 64-bit words. RAM1 contains Tx FIFOs.
0xC160 USB_DWC3_GDBGFIFOSPACE access per field reset 0x420000 — Global Debug FIFO / Queue Space Available.
  [31:16] SPACE_AVAILABLE ro — Space Available [in the selected FIFO / queue], 64-bit words
  [7:0] FIFOQUEUESELECT_PORTSELECT rw — FIFO/Queue Select or port select. Default value, when indicated, is the space available when empty, i.e. the size of the FIFO/queue. PortSelect[3:0] selects the port number when accessing GDBGLTSSM register. FifoQueueSelect[7:0]: see below.
